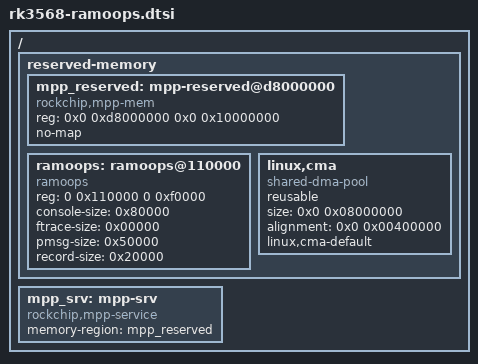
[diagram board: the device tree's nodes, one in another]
/ {
	reserved-memory {
		#address-cells = <2>;
		#size-cells = <2>;
		ranges;

		mpp_reserved: mpp-reserved@d8000000 {
			compatible = "rockchip,mpp-mem";
			reg = <0x0 0xd8000000 0x0 0x10000000>;
			no-map;
		};

		ramoops: ramoops@110000 {
			compatible = "ramoops";
			reg = <0 0x110000 0 0xf0000>;
			console-size = <0x80000>;
			ftrace-size = <0x00000>;
			pmsg-size = <0x50000>;
			record-size = <0x20000>;
		};

		// CMA 配置 - 128MB
		linux,cma {
			compatible = "shared-dma-pool";
			reusable;
			size = <0x0 0x08000000>;
			alignment = <0x0 0x00400000>;
			linux,cma-default;
		};
	};

	mpp_srv: mpp-srv {
		compatible = "rockchip,mpp-service";
		memory-region = <&mpp_reserved>;
		status = "okay";
	};

};

